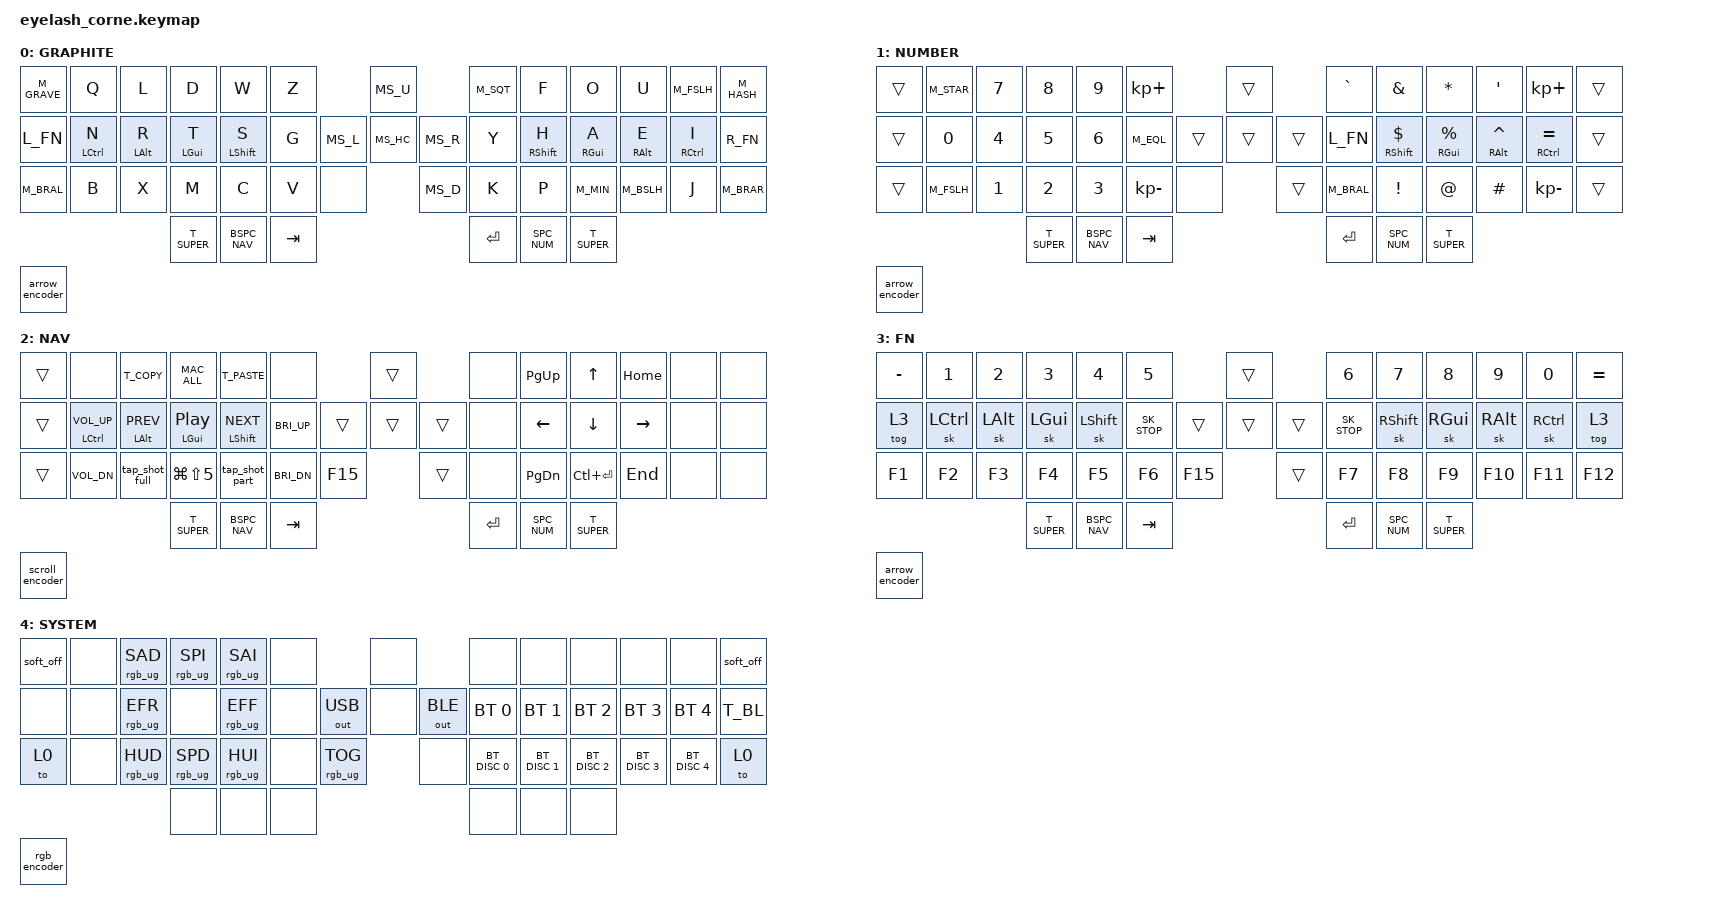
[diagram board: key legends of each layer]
#include <behaviors.dtsi>
#include <dt-bindings/zmk/bt.h>
#include <dt-bindings/zmk/keys.h>
#include <dt-bindings/zmk/outputs.h>
#include <dt-bindings/zmk/rgb.h>

#include <input/processors.dtsi>

#include "zmk-helpers/helper.h"
#include "zmk-helpers/key-labels/eyelash42.h"

#define XXX &none
#define ___ &trans

// Home-Row Mods Definition

#define KEYS_L      LT0 LT1 LT2 LT3 LT4 LT5 LM0 LM1 LM2 LM3 LM4 LM5 LB0 LB1 LB2 LB3 LB4 LB5
#define KEYS_R      RT0 RT1 RT2 RT3 RT4 RT5 RM0 RM1 RM2 RM3 RM4 RM5 RB0 RB1 RB2 RB3 RB4 RB5
#define THUMBS      LH2 LH1 LH0 RH0 RH1 RH2
#define ENC_PRESS   LEC
#define JOYSTICK    JS0 JS1 JS2 JS3 JS4

#include "adv_layers.dtsi"
#include "adv_functions.dtsi"
#include "mouse.dtsi"
#include "encoder.dtsi"

ZMK_LAYER(GRAPHITE,
    //╭─────────╮  ╭─────────────┬─────────────┬─────────────┬─────────────┬─────────────╮                  ╭──────╮         ╭─────────────┬─────────────┬─────────────┬─────────────┬─────────────╮ ╭─────────╮
       M_GRAVE     &kp Q         &kp L         &kp D         &kp W         &kp Z                             MS_U             M_SQT        &kp F         &kp O         &kp U         M_FSLH            M_HASH
    //├─────────┤  ├─────────────┼─────────────┼─────────────┼─────────────┼─────────────┤           ╭──────┼──────┼──────╮  ├─────────────┼─────────────┼─────────────┼─────────────┼─────────────┤ ├─────────┤
       L_FN        &hml LCTRL N  &hml LALT R   &hml LGUI T   &hml LSHFT S  &kp G                      MS_L   MS_HC  MS_R     &kp Y         &hmr RSHFT H  &hmr RGUI A   &hmr RALT E   &hmr RCTRL I     R_FN
    //├─────────┤  ├─────────────┼─────────────┼─────────────┼─────────────┼─────────────┤  ╭──────╮ ╰──────┼──────┼──────╯  ├─────────────┼─────────────┼─────────────┼─────────────┼─────────────┤ ├─────────┤
       M_BRAL      &kp B         &kp X         &kp M         &kp C         &kp V             XXX             MS_D            &kp K         &kp P          M_MIN         M_BSLH       &kp J         M_BRAR 
    //╰─────────╯  ╰─────────────┴─────────────┼─────────────┼─────────────┼─────────────┤  ╰──────╯        ╰──────╯         ├─────────────┼─────────────┼─────────────┼─────────────┴─────────────╯ ╰─────────╯
                                               T_SUPER         BSPC_NAV     &kp TAB                                            &kp ENTER      SPC_NUM      T_SUPER
    //                                         ╰─────────────┴─────────────┴─────────────╯                                   ╰─────────────┴─────────────┴─────────────╯

    , &arrow_encoder
)

ZMK_LAYER(NUMBER,
    //╭─────────╮ ╭───────────────┬─────────────┬─────────────┬─────────────┬─────────────╮                 ╭──────╮         ╭─────────────┬─────────────┬─────────────┬─────────────┬─────────────╮ ╭──────╮
        ___       M_STAR          &kp N7        &kp N8        &kp N9        &kp KP_PLUS                      ___             &kp GRAVE     &kp AMPS    &kp STAR      &kp SQT       &kp KP_PLUS         ___ 
    //├─────────┤ ├───────────────┼─────────────┼─────────────┼─────────────┼─────────────┤          ╭──────┼──────┼──────╮  ├─────────────┼─────────────┼─────────────┼─────────────┼─────────────┤ ├──────┤
        ___       &kp N0          &kp N4        &kp N5        &kp N6          M_EQL                     ___    ___    ___      L_FN        &hmr RSHFT DLLR &hmr RGUI PRCNT  &hmr RALT CARET  &hmr RCTRL EQUAL  ___ 
    //├─────────┤ ├───────────────┼─────────────┼─────────────┼─────────────┼─────────────┤  ╭──────╮╰──────┼──────┼──────╯  ├─────────────┼─────────────┼─────────────┼─────────────┼─────────────┤ ├──────┤
        ___       M_FSLH          &kp N1        &kp N2        &kp N3        &kp KP_MINUS       XXX           ___               M_BRAL      &kp EXCL      &kp AT        &kp HASH      &kp KP_MINUS      ___ 
    //╰─────────╯ ╰───────────────┴─────────────┼─────────────┼─────────────┼─────────────┤  ╰──────╯       ╰──────╯         ├─────────────┼─────────────┼─────────────┼───────────────────────────╯ ╰──────╯
                                                T_SUPER         BSPC_NAV     &kp TAB                                           &kp ENTER      SPC_NUM      T_SUPER
    //                                          ╰─────────────┴─────────────┴─────────────╯                                  ╰─────────────┴─────────────┴─────────────╯

    , &arrow_encoder
)

ZMK_LAYER(NAV,
    //╭──────╮ ╭───────────────────┬─────────────────┬─────────────────┬─────────────────┬─────────────╮                    ╭──────╮         ╭─────────────┬─────────────┬─────────────┬─────────────┬─────────────╮ ╭──────╮
       ___      XXX                T_COPY         MAC_ALL         T_PASTE         XXX                                        ___             XXX          &kp PG_UP     &kp UP        &kp HOME       XXX             XXX
    //├──────┤ ├───────────────────┼─────────────────┼─────────────────┼─────────────────┼─────────────┤             ╭──────┼──────┼──────╮  ├─────────────┼─────────────┼─────────────┼─────────────┼─────────────┤ ├──────┤
       ___     &hml LCTRL C_VOL_UP &hml LALT C_PREV  &hml LGUI C_PP    &hml LSHFT C_NEXT &kp C_BRI_UP                 ___    ___    ___      XXX          &kp LEFT      &kp DOWN      &kp RIGHT      XXX             XXX
    //├──────┤ ├───────────────────┼─────────────────┼─────────────────┼─────────────────┼─────────────┤  ╭──────╮   ╰──────┼──────┼──────╯  ├─────────────┼─────────────┼─────────────┼─────────────┼─────────────┤ ├──────┤
       ___     &kp  C_VOL_DN       &tap_shot_full    &kp LG(LS(N5))    &tap_shot_part    &kp C_BRI_DN       &kp F15          ___             XXX          &kp PG_DN       &kp LC(ENTER) &kp END      XXX             XXX
    //╰──────╯ ╰───────────────────┴─────────────────┼─────────────────┼─────────────────┼─────────────┤  ╰──────╯          ╰──────╯         ├─────────────┼─────────────┼─────────────┼─────────────┴─────────────╯ ╰──────╯
                                                     T_SUPER           BSPC_NAV           &kp TAB                                             &kp ENTER      SPC_NUM      T_SUPER
    //                                               ╰─────────────────┴─────────────────┴─────────────╯                                     ╰─────────────┴─────────────┴─────────────╯

    , &scroll_encoder
)

ZMK_LAYER(FN,
    //╭─────────╮  ╭─────────────┬─────────────┬─────────────┬─────────────┬─────────────╮                ╭─────╮      ╭─────────────┬─────────────┬─────────────┬─────────────┬─────────────╮ ╭──────╮
      &kp MINUS    &kp N1        &kp N2        &kp N3        &kp N4        &kp N5                          ___         &kp N6        &kp N7        &kp N8        &kp N9        &kp N0          &kp EQUAL
    //├─────────┤  ├─────────────┼─────────────┼─────────────┼─────────────┼─────────────┤           ╭────┼─────┼────╮ ├─────────────┼─────────────┼─────────────┼─────────────┼─────────────┤ ├──────┤
      &tog 3       &sk LCTRL     &sk LALT      &sk LGUI      &sk LSHFT      SK_STOP                   ___  ___   ___   SK_STOP       &sk RSHFT     &sk RGUI      &sk RALT      &sk RCTRL       &tog 3
    //├─────────┤  ├─────────────┼─────────────┼─────────────┼─────────────┼─────────────┤  ╭──────╮ ╰────┼─────┼────╯ ├─────────────┼─────────────┼─────────────┼─────────────┼─────────────┤ ├──────┤
      &kp F1       &kp F2        &kp F3        &kp F4        &kp F5        &kp F6           &kp F15        ___         &kp F7        &kp F8        &kp F9        &kp F10       &kp F11         &kp F12
    //╰─────────╯  ╰─────────────┴─────────────┼─────────────┼─────────────┼─────────────┤  ╰──────╯      ╰─────╯      ├─────────────┼─────────────┼─────────────┼─────────────┴─────────────╯ ╰──────╯
                                               T_SUPER         BSPC_NAV      &kp TAB                                     &kp ENTER      SPC_NUM     T_SUPER 
    //                                         ╰─────────────┴─────────────┴─────────────╯                             ╰─────────────┴─────────────┴─────────────╯

    , &arrow_encoder
)

ZMK_LAYER(SYSTEM,
    //╭──────╮       ╭─────────────┬─────────────────┬─────────────────┬─────────────────┬─────────────╮                        ╭────╮                ╭─────────────┬─────────────┬─────────────┬─────────────┬─────────────╮ ╭──────╮
      &soft_off        XXX         &rgb_ug RGB_SAD   &rgb_ug RGB_SPI   &rgb_ug RGB_SAI     XXX                                   XXX                   XXX           XXX           XXX           XXX           XXX            &soft_off
    //├──────┤       ├─────────────┼─────────────────┼─────────────────┼─────────────────┼─────────────┤           ╭────────────┼────┼─────────────╮  ├─────────────┼─────────────┼─────────────┼─────────────┼─────────────┤ ├──────┤
        XXX            XXX         &rgb_ug RGB_EFR     XXX             &rgb_ug RGB_EFF     XXX                     &out OUT_USB  XXX  &out OUT_BLE    &bt BT_SEL 0  &bt BT_SEL 1 &bt BT_SEL 2  &bt BT_SEL 3  &bt BT_SEL 4     T_BL 
    //├──────┤       ├─────────────┼─────────────────┼─────────────────┼─────────────────┼─────────────┤  ╭──────╮ ╰────────────┼────┼─────────────╯  ├─────────────┼─────────────┼─────────────┼─────────────┼─────────────┤ ├──────┤
      &to 0            XXX         &rgb_ug RGB_HUD   &rgb_ug RGB_SPD   &rgb_ug RGB_HUI     XXX            &rgb_ug RGB_TOG        XXX                  &bt BT_DISC 0 &bt BT_DISC 1 &bt BT_DISC 2 &bt BT_DISC 3 &bt BT_DISC 4   &to 0
    //╰──────╯       ╰─────────────┴─────────────────┼─────────────────┼─────────────────┼─────────────┤  ╰──────╯              ╰────╯                ├─────────────┼─────────────┼─────────────┴───────────────────────────╯ ╰──────╯
                                                      XXX               XXX             XXX                                                            XXX           XXX           XXX
    //                                               ╰─────────────────┴─────────────────┴─────────────╯                                              ╰─────────────┴─────────────┴─────────────╯

    , &rgb_encoder
)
